# tcp3d_cfg register map
Vendor: Texas Instruments
Peripheral module from a debugger description file (folder tcp3d).
Registers are 32-bit, read-write, no defined reset value unless marked. A register's access mark holds for its fields unless they carry their own. Offsets are as the file gives them; lines under a group give offsets from that group; [hi:lo] are bit positions; {n}, {i} and the like mark numbered series; 'fields as' and 'values as' point back to an identical list; <NAME> marks a mode.

## TCP3D_3_CFG
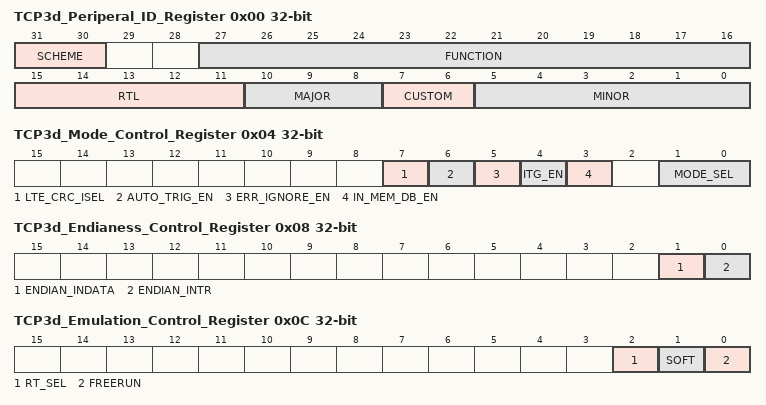
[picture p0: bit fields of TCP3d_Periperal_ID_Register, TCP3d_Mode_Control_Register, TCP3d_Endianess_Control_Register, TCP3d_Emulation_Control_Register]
0x00 TCP3d_Periperal_ID_Register ro
  [31:30] SCHEME — Current scheme
  [27:16] FUNCTION — Function code assigned to TCP3
  [15:11] RTL — RTL Version R code
  [10:8] MAJOR — Major revision X code
  [7:6] CUSTOM — Custom version code
  [5:0] MINOR — Minor revision Y code
0x04 TCP3d_Mode_Control_Register
  [7] LTE_CRC_ISEL — Select initial value used for LTE CRC calculation
  [6] AUTO_TRIG_EN — Enable feature where TCP3 is auto triggered when all of the systematic, parity 0 and parity 1 data for the code block has sent to the TCP3. This eliminates the requirement of triggering the TCP3 by writing to TCP3_TRIG_P0 or TCP3_TRIG_P1.
  [5] ERR_IGNORE_EN — Enable feature where TCP3 only reports errors, but does not stop when an error is detected.
  [4] ITG_EN — Enable internal interleaver table generator for mode selected by MODE_SEL
  [3] IN_MEM_DB_EN — Input memory double buffer enable i.e. ping pong:
  [1:0] MODE_SEL — TCP3 mode i.e. binary, duo-binary, etc
0x08 TCP3d_Endianess_Control_Register
  [1] ENDIAN_INDATA — DSP format of systematic and parity input data in big endian mode. This bit has no effect if in little endian mode.
  [0] ENDIAN_INTR — DSP format of interleaver indices in big endian mode. This bit has no effect if in little endian mode
0x0C TCP3d_Emulation_Control_Register
  [2] RT_SEL — RT_SEL bit
  [1] SOFT — SOFT bit
  [0] FREERUN — FREERUN bit
0x10 TCP3d_End_of_Interrupt_Register
  [7:0] EOI_VECTOR — End of interrupt vector value that distinguishes which interrupt is being acknowledged. This value is outputted on the external eoi_vector interface of the TCP3.
0x14 TCP3d_Soft_Reset_Register
  [0] SOFT_RESET — TCP3 soft reset control
0x100 TCP3d_Execution_Control_Register_Process_0
  [2:0] EXE_CMD — Execution commands
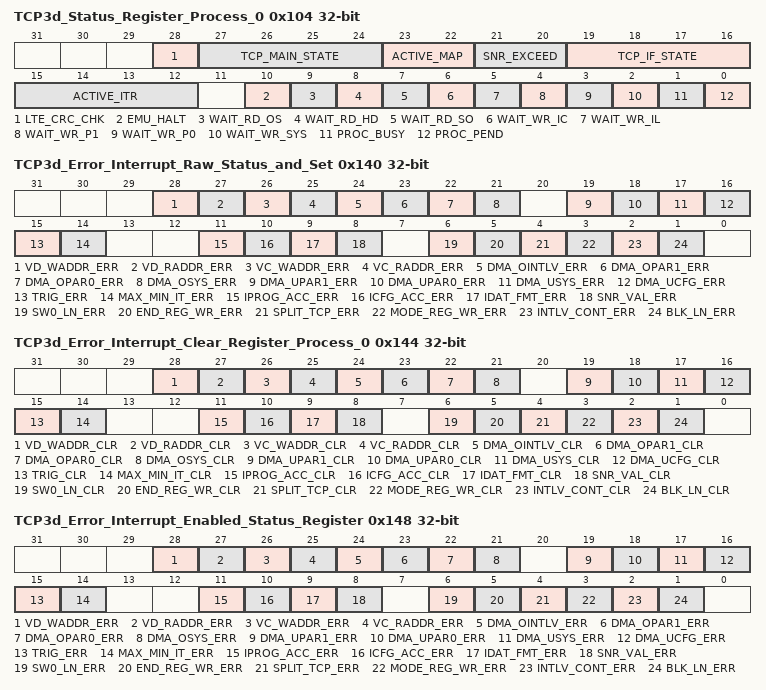
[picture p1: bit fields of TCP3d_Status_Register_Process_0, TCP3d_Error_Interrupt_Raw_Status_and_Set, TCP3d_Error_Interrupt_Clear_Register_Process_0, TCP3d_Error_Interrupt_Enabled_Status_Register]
0x104 TCP3d_Status_Register_Process_0 ro
  [28] LTE_CRC_CHK — LTE CRC Check Status Updated after each CRC calculation in LTE mode; final value held
  [27:24] TCP_MAIN_STATE — State of the TCP3 main state machine (P0 and P1 fields track in double buffer mode)
  [23:22] ACTIVE_MAP — Active MAP Status (P0 and P1 fields track in double buffer mode)
  [21:20] SNR_EXCEED — SNR status (final status held)
  [19:16] TCP_IF_STATE — State of the TCP3 interface state machine (P0 and P1 fields track in double buffer mode)
  [15:12] ACTIVE_ITR — Active iteration status i.e. iteration count Final count held
  [10] EMU_HALT — Indicates if the TCP3 has halted due to emulation (P0 and P1 fields track in double buffer mode)
  [9] WAIT_RD_OS — Indicates if the TCP3 is waiting for output status data to be read
  [8] WAIT_RD_HD — Indicates if the TCP3 is waiting for the hard decision data to be read
  [7] WAIT_RD_SO — Indicates if the TCP3 is waiting for soft output data to be read. In all modes except split mode, wait for all 3 soft output memories (systematic, parity 0, parity 1) to be read. In split mode, only need to wait for systematic output memory to be read
  [6] WAIT_WR_IC — Indicates if the TCP3 is waiting for the input configuration registers to be loaded
  [5] WAIT_WR_IL — Indicates if the TCP3 is waiting for interleaver indices to be loaded
  [4] WAIT_WR_P1 — Indicates if the TCP3 is waiting for the parity 1 data to be loaded
  [3] WAIT_WR_P0 — Indicates if the TCP3 is waiting for the parity 0 data to be loaded
  [2] WAIT_WR_SYS — Indicates if the TCP3 is waiting for the systematic data to be loaded
  [1] PROC_BUSY — Indicates if process is busy. i.e. executing
  [0] PROC_PEND — Indicates when a process has been triggered but has not been serviced yet. In this case this bit stays high until PROC_BUSY is set for the process.
0x108 TCP3d_Event_Set_Register_Process_0 wo
  [0] REVT — REVT event to DMA controller
0x140 TCP3d_Error_Interrupt_Raw_Status_and_Set — TCP3d Error Interrupt Raw Status and Set Register Process 0
  [28] VD_WADDR_ERR — VBUS_DMA Undefined Write Address Access
  [27] VD_RADDR_ERR — VBUS_DMA Undefined Read Address Access
  [26] VC_WADDR_ERR — VBUS_CFG Undefined Write Address Access
  [25] VC_RADDR_ERR — VBUS_CFG Undefined Read Address Access
  [24] DMA_OINTLV_ERR — Interleaver memory DMA transfer overflow error
  [23] DMA_OPAR1_ERR — Parity 1 data memory DMA transfer overflow error
  [22] DMA_OPAR0_ERR — Parity 0 data memory DMA transfer overflow error
  [21] DMA_OSYS_ERR — Systematic data memory DMA transfer overflow error
  [19] DMA_UPAR1_ERR — Parity 1 data memory DMA transfer underflow error. Only valid if auto trigger mode disabled
  [18] DMA_UPAR0_ERR — Parity 0 data memory DMA transfer underflow error. Only valid if auto trigger mode disabled
  [17] DMA_USYS_ERR — Systematic data memory DMA transfer underflow error. Only valid if auto trigger mode disabled
  [16] DMA_UCFG_ERR — Input configuration register DMA transfer underflow error. Only valid if auto trigger mode disabled
  [15] TRIG_ERR — Trigger received for a process that is either busy or has a pending trigger i.e. PROC_BUSY or PROC_PEND set
  [14] MAX_MIN_IT_ERR — Max min iteration error
  [11] IPROG_ACC_ERR — TCP3 in progress memory access error
  [10] ICFG_ACC_ERR — Spurious TCP3 input configuration access error
  [9] IDAT_FMT_ERR — Input data format error
  [8] SNR_VAL_ERR — SNR threshold value error
  [6] SW0_LN_ERR — SW0 Length Error
  [5] END_REG_WR_ERR — Endian register write error
  [4] SPLIT_TCP_ERR — Split TCP3 programming error
  [3] MODE_REG_WR_ERR — Mode register write error
  [2] INTLV_CONT_ERR — Interleaver contention error
  [1] BLK_LN_ERR — Block length error
0x144 TCP3d_Error_Interrupt_Clear_Register_Process_0 wo
  [28] VD_WADDR_CLR — Clear VBUS_DMA undefined write address access error
  [27] VD_RADDR_CLR — Clear VBUS_DMA undefined read address access error
  [26] VC_WADDR_CLR — Clear VBUS_CFG undefined write address access error
  [25] VC_RADDR_CLR — Clear VBUS_CFG undefined read address access error
  [24] DMA_OINTLV_CLR — Clear interleaver memory DMA transfer overflow error interrupt status bit
  [23] DMA_OPAR1_CLR — Clear parity 1 data memory DMA transfer overflow error interrupt status bit
  [22] DMA_OPAR0_CLR — Clear parity 0 data memory DMA transfer overflow error interrupt status bit
  [21] DMA_OSYS_CLR — Clear systematic data memory DMA transfer overflow error interrupt status bit
  [19] DMA_UPAR1_CLR — Clear parity 1 data memory DMA transfer underflow error interrupt status bit
  [18] DMA_UPAR0_CLR — Clear parity 0 data memory DMA transfer underflow error interrupt status bit
  [17] DMA_USYS_CLR — Clear systematic data memory DMA transfer underflow error interrupt status bit
  [16] DMA_UCFG_CLR — Clear input configuration register DMA transfer underflow error interrupt status bit
  [15] TRIG_CLR — Clear trigger error interrupt status bit
  [14] MAX_MIN_IT_CLR — Clear max min iteration error interrupt status bit
  [11] IPROG_ACC_CLR — Clear TCP3 in progress memory access error interrupt status bit
  [10] ICFG_ACC_CLR — Clear spurious TCP3 input configuration access error interrupt status bit
  [9] IDAT_FMT_CLR — Clear input data format error interrupt status bit
  [8] SNR_VAL_CLR — Clear SNR threshold value error interrupt status bit
  [6] SW0_LN_CLR — Clear SW0 length error interrupt status bit
  [5] END_REG_WR_CLR — Clear endian register write error interrupt status bit
  [4] SPLIT_TCP_CLR — Clear split TCP3 programming error interrupt status bit
  [3] MODE_REG_WR_CLR — Clear mode register write error interrupt status bit
  [2] INTLV_CONT_CLR — Clear interleaver contention error interrupt status bit
  [1] BLK_LN_CLR — Clear code block length error interrupt status bit
0x148 TCP3d_Error_Interrupt_Enabled_Status_Register ro — TCP3d Error Interrupt Enabled Status Register Process 0
  [28] VD_WADDR_ERR — VBUS_DMA Undefined Write Address Access
  [27] VD_RADDR_ERR — VBUS_DMA Undefined Read Address Access
  [26] VC_WADDR_ERR — VBUS_CFG Undefined Write Address Access
  [25] VC_RADDR_ERR — VBUS_CFG Undefined Read Address Access
  [24] DMA_OINTLV_ERR — Interleaver memory DMA transfer overflow error
  [23] DMA_OPAR1_ERR — Parity 1 data memory DMA transfer overflow error
  [22] DMA_OPAR0_ERR — Parity 0 data memory DMA transfer overflow error
  [21] DMA_OSYS_ERR — Systematic data memory DMA transfer overflow error
  [19] DMA_UPAR1_ERR — Parity 1 data memory DMA transfer underflow error. Only valid if auto trigger mode disabled
  [18] DMA_UPAR0_ERR — Parity 0 data memory DMA transfer underflow error. Only valid if auto trigger mode disabled
  [17] DMA_USYS_ERR — Systematic data memory DMA transfer underflow error. Only valid if auto trigger mode disabled
  [16] DMA_UCFG_ERR — Input configuration register DMA transfer underflow error. Only valid if auto trigger mode disabled
  [15] TRIG_ERR — Trigger received for a process that is either busy or has a pending trigger. i.e. PROC_BUSY or PROC_PEND set
  [14] MAX_MIN_IT_ERR — Max/min iteration error
  [11] IPROG_ACC_ERR — TCP3 in progress memory access
  [10] ICFG_ACC_ERR — Spurious TCP3 input configuration access error
  [9] IDAT_FMT_ERR — Input data format error
  [8] SNR_VAL_ERR — SNR threshold value error
  [6] SW0_LN_ERR — SW0 Length Error
  [5] END_REG_WR_ERR — Endian register write error
  [4] SPLIT_TCP_ERR — Split TCP3 programming error
  [3] MODE_REG_WR_ERR — Mode register write error
  [2] INTLV_CONT_ERR — Interleaver contention error
  [1] BLK_LN_ERR — Block length error
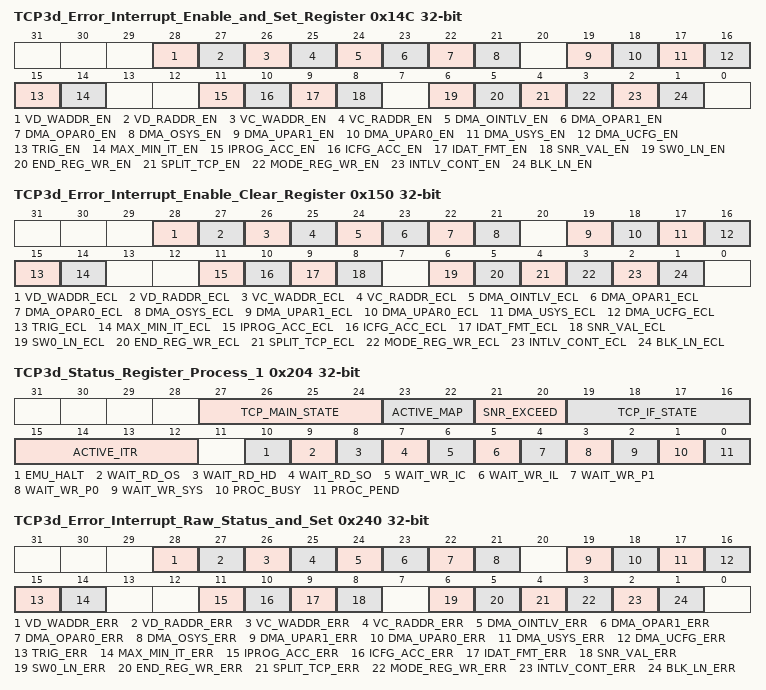
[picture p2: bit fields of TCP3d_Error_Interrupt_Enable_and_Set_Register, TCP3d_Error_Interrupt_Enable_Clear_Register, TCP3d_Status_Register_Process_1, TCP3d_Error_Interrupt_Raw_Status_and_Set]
0x14C TCP3d_Error_Interrupt_Enable_and_Set_Register — TCP3d Error Interrupt Enable and Set Register Process 0
  [28] VD_WADDR_EN — VBUS_DMA Undefined Write Address Access
  [27] VD_RADDR_EN — VBUS_DMA Undefined Read Address Access
  [26] VC_WADDR_EN — VBUS_CFG Undefined Write Address Access
  [25] VC_RADDR_EN — VBUS_CFG Undefined Read Address Access
  [24] DMA_OINTLV_EN — Interleaver memory DMA transfer overflow error
  [23] DMA_OPAR1_EN — Parity 1 data memory DMA transfer overflow error
  [22] DMA_OPAR0_EN — Parity 0 data memory DMA transfer overflow error
  [21] DMA_OSYS_EN — Systematic data memory DMA transfer overflow error
  [19] DMA_UPAR1_EN — Parity 1 data memory DMA transfer underflow error
  [18] DMA_UPAR0_EN — Parity 0 data memory DMA transfer underflow error
  [17] DMA_USYS_EN — Systematic data memory DMA transfer underflow error
  [16] DMA_UCFG_EN — Input configuration register DMA transfer underflow error
  [15] TRIG_EN — Trigger error
  [14] MAX_MIN_IT_EN — Max min iteration error
  [11] IPROG_ACC_EN — TCP3 in progress memory access error
  [10] ICFG_ACC_EN — Spurious TCP3 input configuration access error
  [9] IDAT_FMT_EN — Input data format error
  [8] SNR_VAL_EN — SNR threshold value error
  [6] SW0_LN_EN — SW0 length error
  [5] END_REG_WR_EN — Endian register write error
  [4] SPLIT_TCP_EN — Split TCP3 programming error
  [3] MODE_REG_WR_EN — Mode register write error
  [2] INTLV_CONT_EN — Interleaver contention error
  [1] BLK_LN_EN — Block length error
0x150 TCP3d_Error_Interrupt_Enable_Clear_Register wo — TCP3d Error Interrupt Enable Clear Register Process 0
  [28] VD_WADDR_ECL — Clear VBUS_DMA undefined write address access error interrupt enable
  [27] VD_RADDR_ECL — Clear VBUS_DMA undefined read address access error interrupt enable
  [26] VC_WADDR_ECL — Clear VBUS_CFG undefined write address access error interrupt enable
  [25] VC_RADDR_ECL — Clear VBUS_CFG undefined read address access error interrupt enable
  [24] DMA_OINTLV_ECL — Clear interleaver memory DMA transfer overflow error interrupt enable
  [23] DMA_OPAR1_ECL — Clear parity 1 data memory DMA transfer overflow error interrupt enable
  [22] DMA_OPAR0_ECL — Clear parity 0 data memory DMA transfer overflow error interrupt enable
  [21] DMA_OSYS_ECL — Clear systematic data memory DMA transfer overflow error interrupt enable
  [19] DMA_UPAR1_ECL — Clear parity 1 data memory DMA transfer underflow error interrupt enable
  [18] DMA_UPAR0_ECL — Clear parity 0 data memory DMA transfer underflow error interrupt enable
  [17] DMA_USYS_ECL — Clear systematic data memory DMA transfer underflow error interrupt enable
  [16] DMA_UCFG_ECL — Clear input configuration register DMA transfer underflow error interrupt enable
  [15] TRIG_ECL — Clear trigger error interrupt enable
  [14] MAX_MIN_IT_ECL — Clear max min iteration error interrupt enable
  [11] IPROG_ACC_ECL — Clear TCP3 in progress memory access error interrupt enable
  [10] ICFG_ACC_ECL — Clear spurious TCP3 input configuration access error interrupt enable
  [9] IDAT_FMT_ECL — Clear input data format value error interrupt enable
  [8] SNR_VAL_ECL — Clear SNR threshold value error interrupt enable
  [6] SW0_LN_ECL — Clear SW0 length error interrupt enable
  [5] END_REG_WR_ECL — Clear endian register write error interrupt enable
  [4] SPLIT_TCP_ECL — Clear split TCP3 programming error interrupt enable
  [3] MODE_REG_WR_ECL — Clear mode register write error interrupt enable
  [2] INTLV_CONT_ECL — Clear interleaver contention error interrupt enable
  [1] BLK_LN_ECL — Clear code block length error interrupt enable
0x200 TCP3d_Execution_Control_Register_Process_1
  [2:0] EXE_CMD — Execution commands
0x204 TCP3d_Status_Register_Process_1 ro
  [27:24] TCP_MAIN_STATE — State of the TCP3 main state machine (P0 and P1 fields track in double buffer mode)
  [23:22] ACTIVE_MAP — Active MAP Status (P0 and P1 fields track in double buffer mode)
  [21:20] SNR_EXCEED — SNR status (final status held)
  [19:16] TCP_IF_STATE — State of the TCP3 interface state machine (P0 and P1 fields track in double buffer mode)
  [15:12] ACTIVE_ITR — Active iteration status i.e. iteration count Final count held
  [10] EMU_HALT — Indicates if the TCP3 has halted due to emulation (P0 and P1 fields track in double buffer mode)
  [9] WAIT_RD_OS — Indicates if the TCP3 is waiting for output status data to be read
  [8] WAIT_RD_HD — Indicates if the TCP3 is waiting for the hard decision data to be read
  [7] WAIT_RD_SO — Indicates if the TCP3 is waiting for soft output data to be read. In all modes except split mode, wait for all 3 soft output memories (systematic, parity 0, parity 1) to be read. In split mode, only need to wait for systematic output memory to be read
  [6] WAIT_WR_IC — Indicates if the TCP3 is waiting for the input configuration registers to be loaded
  [5] WAIT_WR_IL — Indicates if the TCP3 is waiting for interleaver indices to be loaded
  [4] WAIT_WR_P1 — Indicates if the TCP3 is waiting for the parity 1 data to be loaded
  [3] WAIT_WR_P0 — Indicates if the TCP3 is waiting for the parity 0 data to be loaded
  [2] WAIT_WR_SYS — Indicates if the TCP3 is waiting for the systematic data to be loaded
  [1] PROC_BUSY — Indicates if process is busy. i.e. executing
  [0] PROC_PEND — Indicates when a process has been triggered but has not been serviced yet. In this case this bit stays high until PROC_BUSY is set for the process.
0x208 TCP3d_Event_Set_Register_Process_1 wo
  [0] REVT — REVT event to DMA controller
0x240 TCP3d_Error_Interrupt_Raw_Status_and_Set — TCP3d Error Interrupt Raw Status and Set Register Process 1
  fields as TCP3d_Error_Interrupt_Raw_Status_and_Set
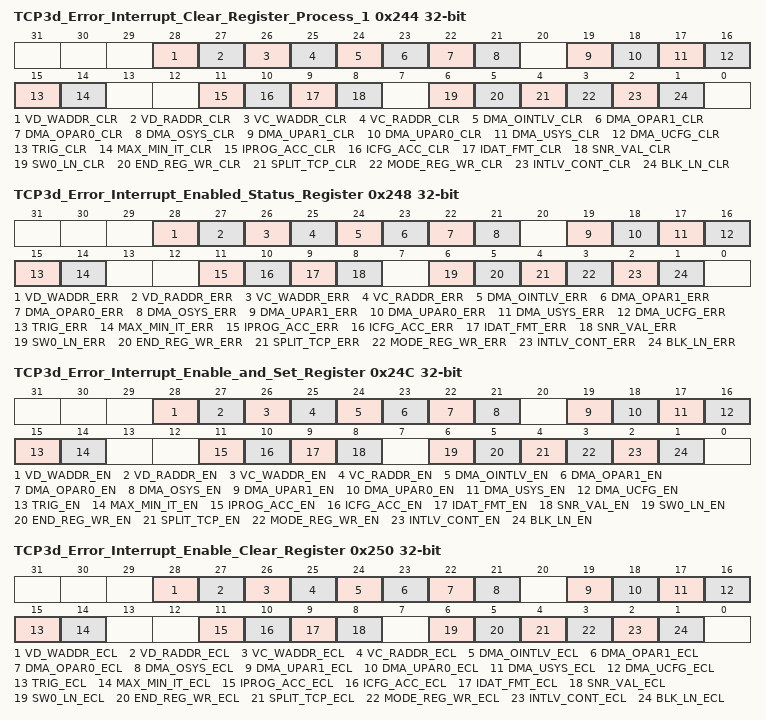
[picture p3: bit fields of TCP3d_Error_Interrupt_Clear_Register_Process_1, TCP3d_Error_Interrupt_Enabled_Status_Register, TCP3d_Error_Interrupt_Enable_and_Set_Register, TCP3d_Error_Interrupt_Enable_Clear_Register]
0x244 TCP3d_Error_Interrupt_Clear_Register_Process_1 wo
  fields as TCP3d_Error_Interrupt_Clear_Register_Process_0
0x248 TCP3d_Error_Interrupt_Enabled_Status_Register ro — TCP3d Error Interrupt Enabled Status Register Process 1
  fields as TCP3d_Error_Interrupt_Enabled_Status_Register
0x24C TCP3d_Error_Interrupt_Enable_and_Set_Register — TCP3d Error Interrupt Enable and Set Register Process 1
  fields as TCP3d_Error_Interrupt_Enable_and_Set_Register
0x250 TCP3d_Error_Interrupt_Enable_Clear_Register wo — TCP3d Error Interrupt Enable Clear Register Process 1
  fields as TCP3d_Error_Interrupt_Enable_Clear_Register
